# STM32U595 register map
File version: 1.0
CPU: CM33 r0p1, little endian, MPU, FPU, 4 interrupt priority bits
Registers are 32-bit, read-write, reset 0x0 unless marked. A register's access mark holds for its fields unless they carry their own. Offsets are from the block's base; [hi:lo] are bit positions; {n}, {i} and the like mark numbered series; 'fields as' and 'values as' point back to an identical list.

## ADC4
Base 0x46021000
Same registers: SEC_ADC4 0x56021000
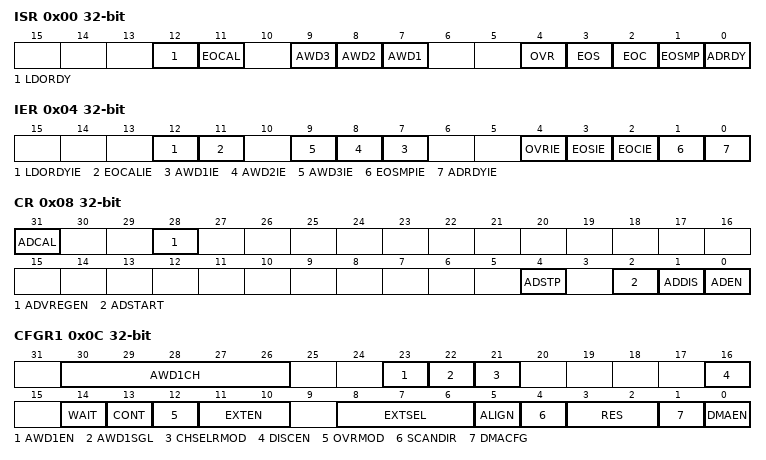
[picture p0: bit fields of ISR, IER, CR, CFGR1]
0x00 ISR — ADC interrupt and status register
  [12] LDORDY
    on read: 0=Disabled (ADC voltage regulator disabled); 1=Enabled (ADC voltage regulator enabled)
  [11] EOCAL
    on read: 0=NotComplete (Calibration is not complete); 1=Complete (Calibration is complete) | on write: 1=Clear the end of calibration flag
  [n+6] AWD{n} (n=1..3) — Analog watchdog {n} flag
    on read: 0=NoEvent (No analog watchdog x event occurred (or the flag event was already acknowledged and cleared by software)); 1=Event (Analog watchdog x event occurred) | on write: 1=Clear the analog watchdog x event flag
  [4] OVR
    on read: 0=No overrun occurred (or the flag event was already acknowledged and cleared by software); 1=Overrun has occurred | on write: 1=Clear the overrun flag
  [3] EOS
    on read: 0=NotComplete (Regular conversions sequence not complete (or the flag event was already acknowledged and cleared by software)); 1=Complete (Regular conversions sequence complete) | on write: 1=Clear the regular conversion sequence flag
  [2] EOC
    on read: 0=NotComplete (Regular channel conversion not complete (or the flag event was already acknowledged and cleared by software)); 1=Complete (Regular channel conversion complete) | on write: 1=Clear the regular channel conversion flag
  [1] EOSMP
    on read: 0=NotAtEnd (Not at the end of the sampling phase (or the flag event was already acknowledged and cleared by software)); 1=AtEnd (End of sampling phase reached) | on write: 1=Clear the sampling phase flag
  [0] ADRDY
    on read: 0=NotReady (ADC not yet ready to start conversion (or the flag event was already acknowledged and cleared by software)); 1=Ready (ADC is ready to start conversion) | on write: 1=Clear the ADC ready flag
0x04 IER — ADC interrupt enable register
  [12] LDORDYIE
    0=Disabled (LDO ready interrupt disabled); 1=Enabled (LDO ready interrupt enabled. An interrupt is generated when the LDO output is ready.)
  [11] EOCALIE
    0=Disabled (End of calibration interrupt disabled); 1=Enabled (End of calibration interrupt enabled)
  [n+6] AWD{n}IE (n=1..3) — Analog watchdog {n} interrupt enable
    0=Disabled (Analog watchdog x interrupt disabled); 1=Enabled (Analog watchdog x interrupt enabled)
  [4] OVRIE
    0=Disabled (Overrun interrupt disabled); 1=Enabled (Overrun interrupt enabled. An interrupt is generated when the OVR bit is set.)
  [3] EOSIE
    0=Disabled (EOS interrupt disabled); 1=Enabled (EOS interrupt enabled. An interrupt is generated when the EOS bit is set.)
  [2] EOCIE
    0=Disabled (EOC interrupt disabled); 1=Enabled (EOC interrupt enabled. An interrupt is generated when the EOC bit is set.)
  [1] EOSMPIE
    0=Disabled (EOSMP interrupt disabled); 1=Enabled (EOSMP interrupt enabled. An interrupt is generated when the EOSMP bit is set.)
  [0] ADRDYIE
    0=Disabled (ADRDY interrupt disabled); 1=Enabled (ADRDY interrupt enabled. An interrupt is generated when the ADRDY bit is set.)
0x08 CR — ADC control register
  [31] ADCAL
    on read: 0=NotCalibrating (Calibration complete); 1=Calibrating (Calibration in progress) | on write: 1=StartCalibration (Calibrate the ADC)
  [28] ADVREGEN
    0=Disabled (ADC voltage regulator disabled); 1=Enabled (ADC voltage regulator enabled)
  [4] ADSTP
    on read: 0=NotStopping (No ADC stop regular conversion command ongoing); 1=Stopping (ADSTP command is in progress) | on write: 1=StopConversion (Stop regular conversions ongoing)
  [2] ADSTART
    on read: 0=NotActive (No ADC regular conversion is ongoing); 1=Active (ADC is operating and eventually converting a regular channel) | on write: 1=Start regular conversions
  [1] ADDIS
    on read: 0=NotOngoing (No ADDIS command ongoing); 1=InProgress (An ADDIS command is in progress) | on write: 1=Disable the ADC
  [0] ADEN
    on read: 0=Disabled (ADC is disabled); 1=Enabled (ADC is enabled) | on write: 1=Enabled (Enable the ADC)
0x0C CFGR1 — ADC configuration register
  [30:26] AWD1CH range 0..19
  [23] AWD1EN
    0=Disabled (Analog watchdog 1 disabled on regular channels); 1=Enabled (Analog watchdog 1 enabled on regular channels)
  [22] AWD1SGL
    0=AllChannels (Analog watchdog 1 enabled on all channels); 1=SingleChannel (Analog watchdog 1 enabled on a single channel)
  [21] CHSELRMOD
    0=BitPerInput (Each bit of the ADC_CHSELR register enables an input); 1=Sequence (ADC_CHSELR register is able to sequence up to 8 channels)
  [16] DISCEN
    0=Disabled (Discontinuous mode for regular channels disabled); 1=Enabled (Discontinuous mode for regular channels enabled)
  [14] WAIT
    0=Disabled (Wait conversion mode off); 1=Enabled (Wait conversion mode on)
  [13] CONT
    0=Single conversion mode; 1=Continuous conversion mode
  [12] OVRMOD
    0=Preserve (ADC_DR register is preserved with the old data when an overrun is detected); 1=Overwrite (ADC_DR register is overwritten with the last conversion result when an overrun is detected)
  [11:10] EXTEN
    0=Disabled (Hardware trigger detection disabled (conversions can be launched by software)); 1=RisingEdge (Hardware trigger detection on the rising edge); 2=FallingEdge (Hardware trigger detection on the falling edge); 3=BothEdges (Hardware trigger detection on both the rising and falling edges)
  [8:6] EXTSEL
    0=TIM1_TRGO2; 1=TIM1_OC4; 2=TIM2_TRGO; 3=TIM15_TRGO; 4=TIM6_TRGO; 5=LPTIM1_CH1; 6=LPTIM3_CH2; 7=EXTI15
  [5] ALIGN
    0=Right alignment; 1=Left alignment
  [4] SCANDIR
    0=Upward scan sequence (from CHSEL0 to CHSEL23); 1=Downward scan sequence (from CHSEL23 to CHSEL0)
  [3:2] RES
    0=TwelveBit (12 bits); 1=TenBit (10 bits); 2=EightBit (8 bits); 3=SixBit (6 bits)
  [1] DMACFG
    0=One-shot mode selected; 1=Circular mode selected
  [0] DMAEN
    0=Disabled (DMA disabled); 1=Enabled (DMA enabled)
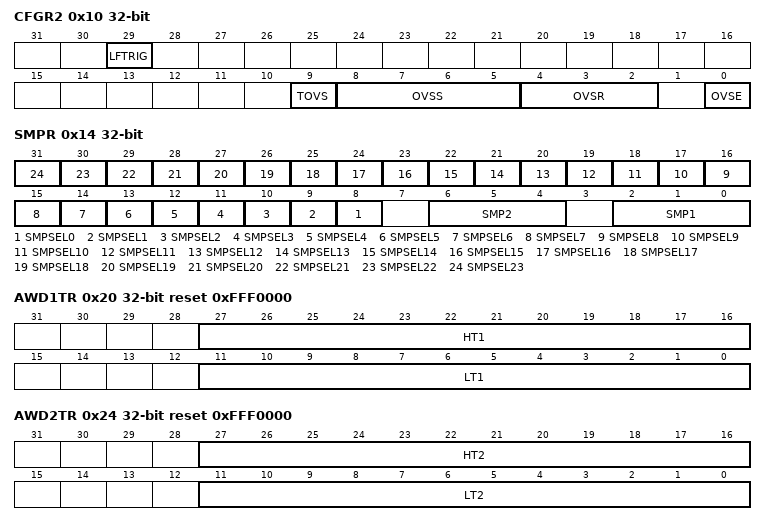
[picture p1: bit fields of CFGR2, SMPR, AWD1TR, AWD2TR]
0x10 CFGR2 — ADC configuration register 2
  [29] LFTRIG
    0=Disabled (Low-frequency trigger mode disabled); 1=Enabled (Low-frequency trigger mode enabled)
  [9] TOVS
    0=Automatic (All oversampled conversions for a channel are done consecutively following a trigger); 1=Triggered (Each oversampled conversion for a channel needs a new trigger)
  [8:5] OVSS range 0..8
  [4:2] OVSR
  [0] OVSE
    0=Disabled (Oversampler disabled); 1=Enabled (Oversampler enabled)
0x14 SMPR — ADC sample time register
  [n+8] SMPSEL{n} (n=0..23) — Channel-{n} sampling time selection
    0=SMP1 (Sampling time of channel x uses the setting of SMP1 register.); 1=SMP2 (Sampling time of channel x uses the setting of SMP2 register.)
  [4n-2:4n-4] SMP{n} (n=1..2) — Sampling time selection {n}
    0=Cycles1_5 (1.5 ADC clock cycles); 1=Cycles3_5 (3.5 ADC clock cycles); 2=Cycles7_5 (7.5 ADC clock cycles); 3=Cycles12_5 (12.5 ADC clock cycles); 4=Cycles19_5 (19.5 ADC clock cycles); 5=Cycles39_5 (39.5 ADC clock cycles); 6=Cycles79_5 (79.5 ADC clock cycles); 7=Cycles814_5 (814.5 ADC clock cycles)
0x20 AWD1TR reset 0xFFF0000 — ADC watchdog threshold register
  [27:16] HT1, [11:0] LT1
0x24 AWD2TR reset 0xFFF0000 — ADC watchdog threshold register
  [27:16] HT2, [11:0] LT2
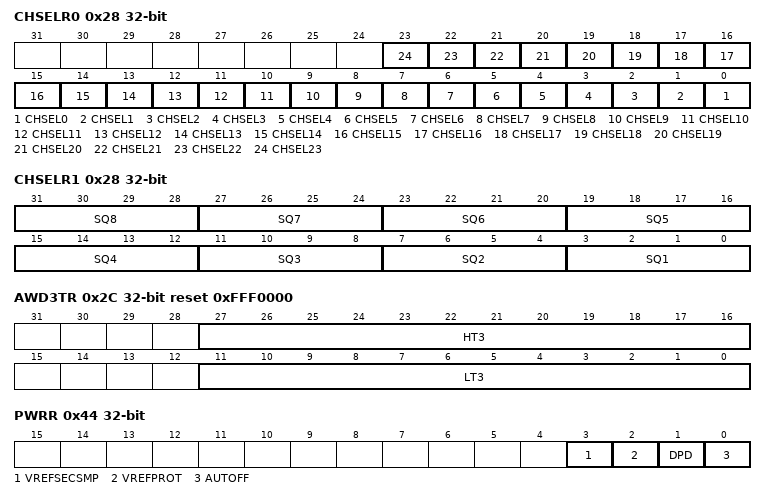
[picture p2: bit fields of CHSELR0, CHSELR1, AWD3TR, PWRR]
0x28 CHSELR0 — ADC channel selection register [alternate]
  [n] CHSEL{n} (n=0..23) — Channel-{n} selection
    0=Disabled (Input channel x is not selected for conversion); 1=Enabled (Input channel x is selected for conversion)
0x28 CHSELR1 (alternate view of CHSELR0) — ADC channel selection register [alternate]
  [4n-1:4n-4] SQ{n} (n=1..8) — {n} conversion of the sequence
    {v}=Channel{v} (CH{v}) (v=0..14); 15=No channel selected (End of sequence)
0x2C AWD3TR reset 0xFFF0000 — ADC watchdog threshold register
  [27:16] HT3, [11:0] LT3
0x40 DR ro — ADC data register
  [15:0] DATA
0x44 PWRR — ADC data register
  [3] VREFSECSMP
    0=Disabled (VREF+ second sample disabled); 1=Enabled (VREF+ second sample enabled)
  [2] VREFPROT
    0=Disabled (VREF+ protection disabled); 1=Enabled (VREF+ protection enabled)
  [1] DPD
    0=Disabled (Deep-power-down mode disabled); 1=Enabled (Deep-power-down mode enabled)
  [0] AUTOFF
    0=Disabled (Auto-off mode disabled); 1=Enabled (Auto-off mode enabled)
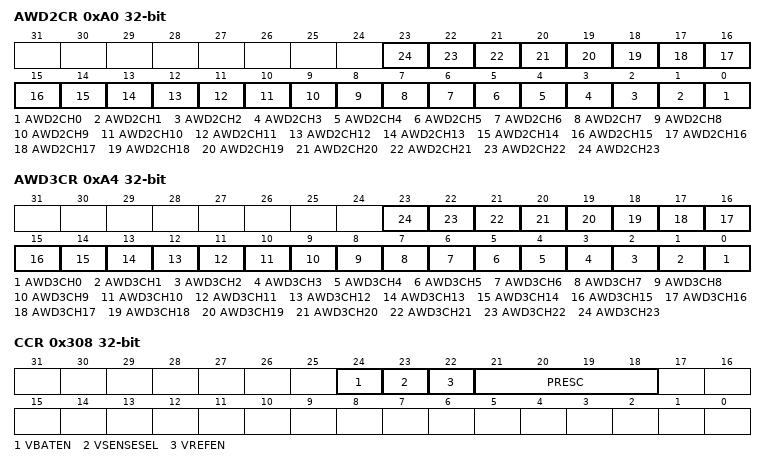
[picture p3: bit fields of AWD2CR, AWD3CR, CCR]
0xA0 AWD2CR — ADC Analog Watchdog 2 Configuration register
  [n] AWD2CH{n} (n=0..23) — AWD2CH{n}
    0=Disabled (ADC analog input channel x is not monitored by AWDy); 1=Enabled (ADC analog input channel x is monitored by AWDy)
0xA4 AWD3CR — ADC Analog Watchdog 3 Configuration register
  [n] AWD3CH{n} (n=0..23) — AWD3CH{n}
    values as AWD2CR.AWD2CH0
0xB4 CALFACT — ADC Calibration factor
  [6:0] CALFACT
0xD0 OR — ADC option register
  [0] CHN21SEL
    0=Out1 (dac1_out1 selected); 1=Out2 (dac1_out2 selected)
0x308 CCR — ADC common configuration register
  [24] VBATEN
    0=Disabled (VBAT channel disabled); 1=Enabled (VBAT channel enabled)
  [23] VSENSESEL — TSEN
    0=Disabled (Temperature sensor channel disabled); 1=Enabled (Temperature sensor channel enabled)
  [22] VREFEN
    0=Disabled (VREFINT channel disabled); 1=Enabled (VREFINT channel enabled)
  [21:18] PRESC
    0=Div1 (Input ADC clock not divided); 1=Div2 (Input ADC clock divided by 2); 2=Div4 (Input ADC clock divided by 4); 3=Div6 (Input ADC clock divided by 6); 4=Div8 (Input ADC clock divided by 8); 5=Div10 (Input ADC clock divided by 10); 6=Div12 (Input ADC clock divided by 12); 7=Div16 (Input ADC clock divided by 16); 8=Div32 (Input ADC clock divided by 32); 9=Div64 (Input ADC clock divided by 64); 10=Div128 (Input ADC clock divided by 128); 11=Div256 (Input ADC clock divided by 256)
